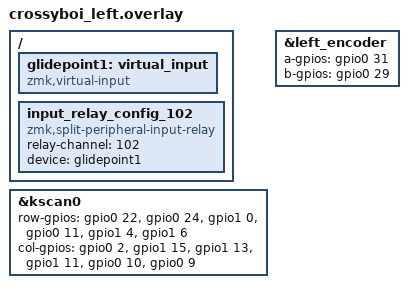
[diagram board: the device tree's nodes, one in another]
/*
 * Copyright (c) 2022 The ZMK Contributors
 *
 * SPDX-License-Identifier: MIT
 */

#include "crossyboi.dtsi"

&kscan0 {
    row-gpios
      = <&gpio0 22 (GPIO_ACTIVE_HIGH | GPIO_PULL_DOWN)>
      , <&gpio0 24 (GPIO_ACTIVE_HIGH | GPIO_PULL_DOWN)>
      , <&gpio1 0 (GPIO_ACTIVE_HIGH | GPIO_PULL_DOWN)>
      , <&gpio0 11 (GPIO_ACTIVE_HIGH | GPIO_PULL_DOWN)>
      , <&gpio1 4 (GPIO_ACTIVE_HIGH | GPIO_PULL_DOWN)>
      , <&gpio1 6 (GPIO_ACTIVE_HIGH | GPIO_PULL_DOWN)>
      ;

    col-gpios
      = <&gpio0 2 GPIO_ACTIVE_HIGH>
      , <&gpio1 15 GPIO_ACTIVE_HIGH>
      , <&gpio1 13 GPIO_ACTIVE_HIGH>
      , <&gpio1 11 GPIO_ACTIVE_HIGH>
      , <&gpio0 10 GPIO_ACTIVE_HIGH>
      , <&gpio0 9 GPIO_ACTIVE_HIGH>
      ;
};

&left_encoder {
    status = "okay";
	a-gpios = <&gpio0 31 (GPIO_ACTIVE_HIGH | GPIO_PULL_UP)>;
	b-gpios = <&gpio0 29 (GPIO_ACTIVE_HIGH | GPIO_PULL_UP)>;
};
/*
&chosen {
  zephyr,display = &nice_view;
};

// nice view bus
&nice_view_spi {
  status = "okay";
};

&nice_view {
  status = "okay";
};
*/
/ {
    /* define virtual input, will be resurrected for emitting input event */
	/* NOTE: set `device = <&glidepoint1>` in `zmk,input-listener` */
	glidepoint1: virtual_input {
		compatible = "zmk,virtual-input";
	};

	/* for central side, define (relay-channel)-to-(virtual-input) mapping */
	input_relay_config_102 {
		compatible = "zmk,split-peripheral-input-relay";
		
		/* channel id, used to filter incoming input event from split peripheral */
		/* NOTE: should matching relay-channel on peripheral overlay */
		relay-channel = <102>;

		/* virtual input device on central, which used to emit input event as an agent device */
		device = <&glidepoint1>;
	};
};

